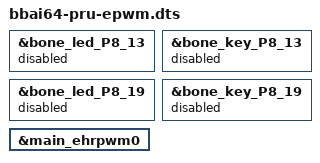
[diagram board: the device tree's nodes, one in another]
/dts-v1/;
/plugin/;

/* Disable default kernel-level device mappings to free P8_13 and P8_19 */
&bone_led_P8_13 { status = "disabled"; };
&bone_key_P8_13 { status = "disabled"; };
&bone_led_P8_19 { status = "disabled"; };
&bone_key_P8_19 { status = "disabled"; };

/* Enable EHRPWM0. The base device tree already includes both P8_13 and P8_19 in its default pinctrl-0 */
&main_ehrpwm0 {
    status = "okay";
};
